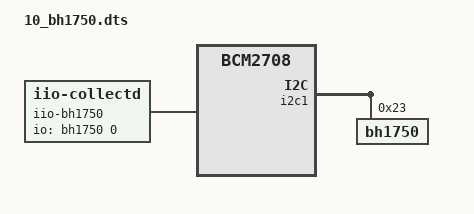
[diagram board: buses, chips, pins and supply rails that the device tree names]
/dts-v1/;
/plugin/;

/ {
  compatible = "brcm,bcm2708"; /* probably will soon be bcm2835? */

  fragment@0 {
    target = <&i2c1>; /* NOTE: cannot use i2c_arm here! */
    __overlay__ {
      #address-cells = <1>; /* 1 for i2c devices */
      #size-cells = <0>;    /* 0 for i2c devices */
      status = "okay";

      bh1750: bh1750@23 {
        /* i2c */
        compatible = "bh1750";
        reg = <0x23>;
        status = "okay";

        /* iio */
        #io-channel-cells = <1>; /* 1 for multiple channels */

        /* iio/light/bh1750 special config */
        /* (NONE) */
      };
    };
  };

  /* iio-hwmon bridge (modified version) */
  /* This mirrors iio channels to hwmon, which can be hooked to collectd. */
  fragment@1 {
    target-path = "/";
    __overlay__ {
      iio-bh1750 {
        compatible = "iio-collectd";
        io-channels = <&bh1750 0>;
        io-channel-names = "Ambient";
      };
    };
  };
};
